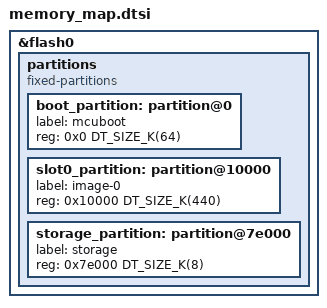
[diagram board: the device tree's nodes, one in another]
/*
 * Copyright (c) 2026 Nordic Semiconductor ASA
 *
 * SPDX-License-Identifier: LicenseRef-Nordic-5-Clause
 */

&flash0 {
	/delete-node/ partitions;

	partitions {
		compatible = "fixed-partitions";
		#address-cells = <1>;
		#size-cells = <1>;

		boot_partition: partition@0 {
			label = "mcuboot";
			reg = <0x0 DT_SIZE_K(64)>;
		};

		slot0_partition: partition@10000 {
			label = "image-0";
			reg = <0x10000 DT_SIZE_K(440)>;
		};

		storage_partition: partition@7e000 {
			label = "storage";
			reg = <0x7e000 DT_SIZE_K(8)>;
		};
	};
};
